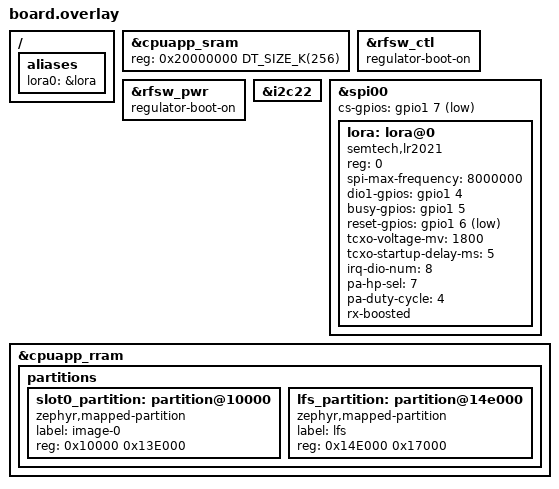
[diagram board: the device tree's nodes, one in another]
/*
 * SPDX-License-Identifier: MIT
 * XIAO nRF54L15 + Wio-LR2021 LoRa (Semtech LR2021)
 *
 * Pin mapping (XIAO nRF54L15 connector → Wio-LR2021):
 * - D0  (P1.04)  = DIO8/IRQ
 * - D1  (P1.05)  = BUSY
 * - D2  (P1.06)  = RESET
 * - D3  (P1.07)  = CS (NSS)
 * - D4  (P1.10)  = I2C SDA (OLED)
 * - D5  (P1.11)  = I2C SCL (OLED)
 * - D8  (P2.01)  = SPI SCK  (spi00)
 * - D9  (P2.04)  = SPI MISO (spi00)
 * - D10 (P2.02)  = SPI MOSI (spi00)
 *
 * Console: UART20 (P1.09 TX, P1.08 RX) via SAMD11 CMSIS-DAP bridge → USB CDC
 * Flash: RRAM (not traditional NV flash)
 * Flash via: SWD through SAMD11 CMSIS-DAP (west flash / openocd)
 */

#include <zephyr/dt-bindings/gpio/gpio.h>

/ {
	aliases {
		lora0 = &lora;
	};
};

/*
 * The nRF54L15 has 256 KB SRAM total, split as 188 KB (cpuapp) + 68 KB
 * (cpuflpr) by default. We don't use the FLPR core, so give all 256 KB
 * to cpuapp.
 */
&cpuapp_sram {
	reg = <0x20000000 DT_SIZE_K(256)>;
	ranges = <0x0 0x20000000 DT_SIZE_K(256)>;
};

/*
 * RF switch regulators on the LoRa Plus expansion board.
 * These control the antenna path — without them, the LR2021 has no RF output.
 * rfsw_ctl (P2.5) = RF switch control, rfsw_pwr (P2.3) = RF switch power.
 */
&rfsw_ctl {
	regulator-boot-on;
	status = "okay";
};

&rfsw_pwr {
	regulator-boot-on;
	status = "okay";
};

/*
 * SSD1306 128x64 OLED on the LoRa Plus expansion board.
 * Connected via I2C22 (D4=P1.10 SDA, D5=P1.11 SCL) at address 0x3c.
 */
&i2c22 {
	status = "okay";
};

/* LR2021 (SX1262-compatible) on spi00 */
&spi00 {
	cs-gpios = <&gpio1 7 GPIO_ACTIVE_LOW>;  /* D3 = P1.07 CS */

	lora: lora@0 {
		compatible = "semtech,lr2021";
		reg = <0>;
		spi-max-frequency = <8000000>;

		/* LoRa control pins */
		dio1-gpios = <&gpio1 4 (GPIO_PULL_DOWN | GPIO_ACTIVE_HIGH)>;  /* D0 = P1.04 DIO8/IRQ */
		busy-gpios = <&gpio1 5 GPIO_ACTIVE_HIGH>;   /* D1 = P1.05 BUSY */
		reset-gpios = <&gpio1 6 GPIO_ACTIVE_LOW>;    /* D2 = P1.06 RESET */

		/* Wio-LR2021 board has TCXO at 1.8V (required for proper RX) */
		tcxo-voltage-mv = <1800>;
		tcxo-startup-delay-ms = <5>;

		/*
		 * Wio-LR2021 handles RF switch internally — no DIO5/DIO6 needed.
		 * rfsw_ctl/rfsw_pwr regulators POWER the antenna circuitry only.
		 * Do NOT add rfswitch-* properties for Wio-LR2021 (breaks RX).
		 * ProMicro LR2021 (NiceRF) DOES use DIO5/DIO6 — different module!
		 */

		/* IRQ on DIO8 (not default DIO9) — Wio-LR2021 wiring */
		irq-dio-num = <8>;

		/* PA settings — max power for sub-GHz */
		pa-hp-sel = <7>;
		pa-duty-cycle = <4>;

		/* Boosted RX for better sensitivity */
		rx-boosted;
	};
};

/*
 * RRAM partitions — repartition for ZephCore
 * Total RRAM: 1428KB (0x165000)
 *
 * Default layout: boot(64KB) + slot0(664KB) + slot1(664KB) + storage(36KB)
 * New layout (no MCUboot DFU for companion device):
 *
 * 0x00000 - 0x10000   (64KB)   MCUboot (reserved, even if unused)
 * 0x10000 - 0x14E000  (1272KB) Application (slot0 — expanded into slot1 space)
 * 0x14E000 - 0x165000 (92KB)   LittleFS (identity, contacts, channels, BLE bonds)
 */
/delete-node/ &slot0_partition;
/delete-node/ &slot1_partition;
/delete-node/ &storage_partition;

&cpuapp_rram {
	partitions {
		/* Application — expanded to use slot1 space */
		slot0_partition: partition@10000 {
			compatible = "zephyr,mapped-partition";
			label = "image-0";
			reg = <0x10000 0x13E000>;  /* 1272KB */
		};

		/* LittleFS 92KB for DataStore + file-based BLE settings */
		lfs_partition: partition@14e000 {
			compatible = "zephyr,mapped-partition";
			label = "lfs";
			reg = <0x14E000 0x17000>;
		};
	};
};

/* LittleFS auto-mount — standard /lfs mount point */
#include "../../common/filesystem.dtsi"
